# A31G324 register map
Vendor: ABOV Semiconductor Co., Ltd.; Series: A31G324; File version: 1.0
CPU: CM0PLUS r0p1, little endian, no MPU, no FPU, VTOR, 2 interrupt priority bits
Registers are 32-bit, read-write, reset 0x0 unless marked. A register's access mark holds for its fields unless they carry their own. Offsets are from the block's base; [hi:lo] are bit positions; {n}, {i} and the like mark numbered series.

## CRC — CYCLIC REDUNDANCY CHECK AND CHECKSUM
Base 0x40000300
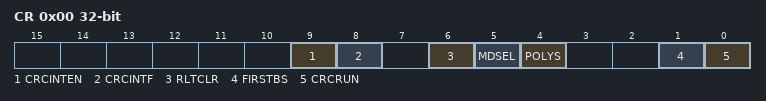
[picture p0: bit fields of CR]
0x00 CR — CRC/Checksum Control Register. Notes: 1. The CRCRLT register and the CRC/Checksum block should be initialized by writing "1b" to the RLTCLR bit before a new CRC/Checksum calculation. 2. The CRCRUN bit should be set to "1b" last time after setting appropriate values to the registers. 3. On the user mode, it will be calculated every writing data to the CRCIN register during CRCRUN==1. 4. On the user mode with SARINC==0, the block is finished by writing "0b" to the CRCRUN bit. 4. It is prohibited writing any data to the CRCIN register during CRCRUN==0. 5. The checksum is calculated by byte unit. Ex) On 0x34A7E991, CRCRLT = 0x34 + 0xA7 + 0xE9 + 0x91.
  [9] CRCINTEN — CRC interrupt enable bit
  [8] CRCINTF — CRC interrupt flag bit
  [6] RLTCLR — CRC/Checksum Result Data Register (CRCRLT) Initialization bit
  [5] MDSEL — CRC/Checksum Selection bit
  [4] POLYS — Polynomial Selection bit (CRC only)
  [1] FIRSTBS — First Shifted-in Selection bit (CRC only)
  [0] CRCRUN — CRC/Checksum Start Control and Busy bit
0x04 IN — CRC/Checksum Input Data Register
  [31:0] INDATA — CRC Input Data bits.
0x08 RLT ro reset 0xFFFF — CRC/Checksum Result Data Register
  [15:0] RLTDATA rw — CRC Result Data bits.
0x0C INIT — CRC/Checksum Initial Data Register
  [15:0] INIDATA — CRC Initial Data bits.

## HSICMU
Base 0x40002B00
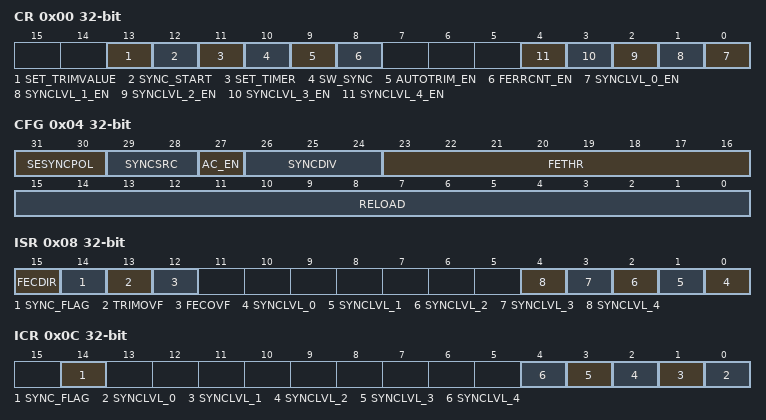
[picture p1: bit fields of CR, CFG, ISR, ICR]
0x00 CR — High Speed Internal OSC Clock Management Unit Control Register
  [13] SET_TRIMVALUE — The value of the trim register is applied to the high speed internal OSC 0: No Action 1: The value of the trim register is applied to the high speed internal OSC
  [12] SYNC_START — Start synchronized timer 0: No Action 1: Start synchronized timer
  [11] SET_TIMER — The value in the Reload register is written to the FERRCNT 0: No Action 1: The value in the Reload register is written to the Frequency Error Rate Counter
  [10] SW_SYNC — Generate Software SYNC event 0: No Action 1: A software SYNC event is generate
  [9] AUTOTRIM_EN — Auto Trim Enable 0: Auto trimming disable 1: Auto trimming enable *This bit enables the automatic hardware adjustment of TRIM bits according to the measured frequency error between two SYNC events. If this bit is set, the TRIM bits are read-only. The TRIM value can be adjusted by hardware by one or two ot three steps at a time, depending on the measured frequency error value. ** Before setting this bit, you must load the trim value into the trim register and set SET_TRIMVALUE BIT to 1.
  [8] FERRCNT_EN — Frequency Error Rate Counter Enable 0: Frequency Error Rate Counter disable 1: Frequency Error Rate Counter enable
  [n] SYNCLVL_{n}_EN (n=0..4) — ERROR LEVEL {n} Interrupt ( Flag ) Enable 0: ERROR LEVEL {n} Interrupt ( Flag ) disable 1: ERROR LEVEL {n} Interrupt ( Flag ) enable
0x04 CFG — High Speed Internal OSC Clock Management Unit Config Register
  [31:30] SESYNCPOL — This bit is set and cleared by software to select the input polarity for the SYNC signal source. 00: Both edge. 01: Rising edge. 10: Falling edge. 11: RESERVED.
  [29:28] SYNCSRC — SYNC Signal Source Selection These bits are set and cleared by software to select the SYNC signal source. 00: Capture Data Update when SOF is successfully received. 01: Capture Data Update when SOF is successfully received and also even when SOF is missed. 10: SOSC CLK. 11: GPIO.
  [27] AC_EN — Auto Clear Enable 0: No Action 1: Auto Clear Enable
  [26:24] SYNCDIV — SYNC Divider These bits are set and cleared by software to control the division factor of the SYNC signal. 000: SYNC not divided (default) 001: SYNC divided by 2 010: SYNC divided by 4 011: SYNC divided by 8 100: SYNC divided by 16 101: SYNC divided by 32 110: SYNC divided by 64 111: SYNC divided by 128
  [23:16] FETHR — Frequency Error Rate Threshold Register FETHR contains the value to be used to evaluate the captured frequency error rate value latched in the FECAP register.
  [15:0] RELOAD — Sync Timer Reload Value RELOAD is the value to be loaded in the Synctimer with each SYNC event.
0x08 ISR ro — High Speed Internal OSC Clock Management Unit Interrupt & Status Register
  [15] FECDIR — Frequency Error Capture Direction 0: count under reload 1: count over reload
  [14] SYNC_FLAG
  [13] TRIMOVF — TRIM Over Flow
  [12] FECOVF — Frequency Error Capture Over Flow
  [n] SYNCLVL_{n} (n=0..4)
0x0C ICR wo — High Speed Internal OSC Clock Management Unit Interrupt & Status Clear Register
  [14] SYNC_FLAG, [n] SYNCLVL_{n} (n=0..4)
0x10 TRIM — High Speed Internal OSC Clock Management Unit TRIM Register
  [7:0] TRIM — TRIM Value
0x14 ATRIM ro — High Speed Internal OSC Clock Management Unit Auto TRIM Register
  [7:0] ATRIM — Auto TRIM Value
0x18 CAP ro — High Speed Internal OSC Clock Management Unit Capture Register
  [15:0] CAP — Capture Value

## TEMP — Temp Sensor
Base 0x40006300
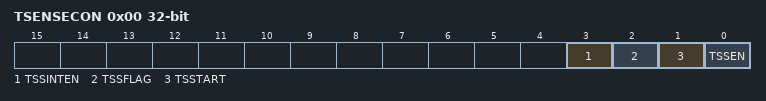
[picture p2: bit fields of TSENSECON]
0x00 TSENSECON — Temp Sensor Control Register
  [3] TSSINTEN — Temp Sensor interrupt enable
    0=DISABLE_TEMPINT (Temp sensor interrupt disabled); 1=ENABLE_TEMPINT (Temp sensor interrupt enabled)
  [2] TSSFLAG — Temp Sensor CNT match flag
  [1] TSSTART — Temp Sensor start
  [0] TSSEN — Temp Sensor enable
0x04 TSREFPEROID reset 0xFFFFF — Temp Sensor Reference Clock Period Register
  [19:0] TSREFPERIOD
0x08 TSSENSECNT ro (reset mask 0xFF) — Temp Sensor Sense Clock Count Register
  [15:0] TSSENSECNT — Temp Sensor Reference Count Register
